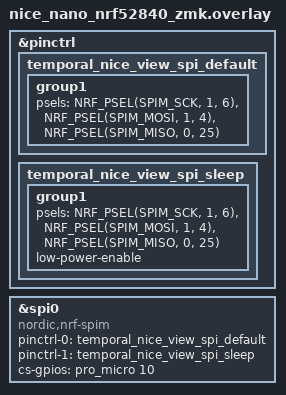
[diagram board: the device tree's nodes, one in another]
/*
 * Copyright (c) 2024 Curtis Bollinger
 *
 * SPDX-License-Identifier: MIT
 *
 * SPI wiring adapted from curbol/temporal-zmk, revision
 * 306ef1f91f27a7ce5f407be3719d508489bb53da.
 */

&pinctrl {
    temporal_nice_view_spi_default: temporal_nice_view_spi_default {
        group1 {
            psels = <NRF_PSEL(SPIM_SCK, 1, 6)>,
                <NRF_PSEL(SPIM_MOSI, 1, 4)>,
                <NRF_PSEL(SPIM_MISO, 0, 25)>;
        };
    };

    temporal_nice_view_spi_sleep: temporal_nice_view_spi_sleep {
        group1 {
            psels = <NRF_PSEL(SPIM_SCK, 1, 6)>,
                <NRF_PSEL(SPIM_MOSI, 1, 4)>,
                <NRF_PSEL(SPIM_MISO, 0, 25)>;
            low-power-enable;
        };
    };
};

nice_view_spi: &spi0 {
    compatible = "nordic,nrf-spim";
    pinctrl-0 = <&temporal_nice_view_spi_default>;
    pinctrl-1 = <&temporal_nice_view_spi_sleep>;
    pinctrl-names = "default", "sleep";
    cs-gpios = <&pro_micro 10 GPIO_ACTIVE_HIGH>;
};
